VERSION ""

NS_ :

BS_:

BU_:

BO_ 1280 HEARTBEAT: 8 Vector__XXX
 SG_ State : 0|8@1+ (1,0) [0|0] "" Vector__XXX
 SG_ Counter : 8|8@1+ (1,0) [0|0] "" Vector__XXX

BO_ 1281 ERROR: 8 Vector__XXX

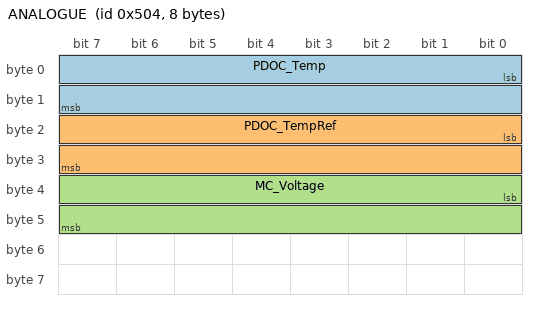
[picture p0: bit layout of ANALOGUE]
BO_ 1284 ANALOGUE: 8 Vector__XXX
 SG_ PDOC_Temp : 0|16@1+ (1,0) [0|0] "" Vector__XXX
 SG_ PDOC_TempRef : 16|16@1+ (1,0) [0|0] "" Vector__XXX
 SG_ MC_Voltage : 32|16@1+ (1,0) [0|0] "" Vector__XXX

BO_ 1107 PERIPHERAL: 8 Vector__XXX
 SG_ DC_Release : 0|8@1+ (1,0) [0|0] "" Vector__XXX
